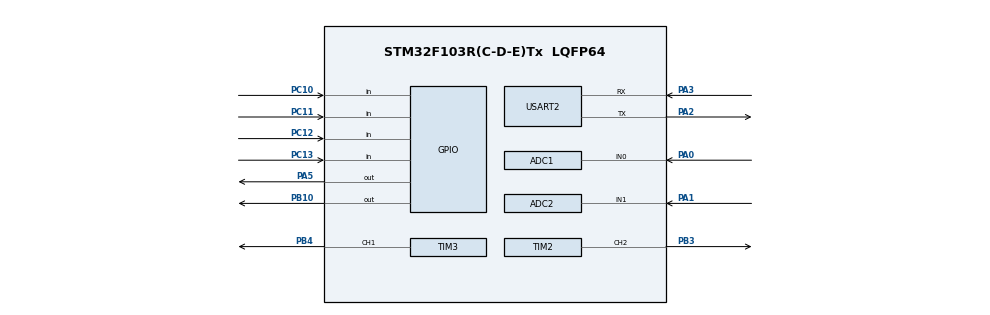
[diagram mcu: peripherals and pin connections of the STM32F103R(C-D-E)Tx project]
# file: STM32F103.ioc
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ADC1.Channel-0\#ChannelRegularConversion=ADC_CHANNEL_0
ADC1.ContinuousConvMode=DISABLE
ADC1.NbrOfConversionFlag=1
ADC1.Rank-0\#ChannelRegularConversion=1
ADC1.SamplingTime-0\#ChannelRegularConversion=ADC_SAMPLETIME_1CYCLE_5
ADC1.master=1
ADC2.Channel-2\#ChannelRegularConversion=ADC_CHANNEL_1
ADC2.NbrOfConversionFlag=1
ADC2.Rank-2\#ChannelRegularConversion=1
ADC2.SamplingTime-2\#ChannelRegularConversion=ADC_SAMPLETIME_1CYCLE_5
Mcu.Family=STM32F1
Mcu.Name=STM32F103R(C-D-E)Tx
Mcu.Package=LQFP64
NVIC.PriorityGroup=NVIC_PRIORITYGROUP_4
PA0-WKUP.Signal=ADCx_IN0
PA1.Signal=ADCx_IN1
PA13.Mode=Serial_Wire
PA13.Signal=SYS_JTMS-SWDIO
PA14.Mode=Serial_Wire
PA14.Signal=SYS_JTCK-SWCLK
PA2.Mode=Asynchronous
PA2.Signal=USART2_TX
PA3.Mode=Asynchronous
PA3.Signal=USART2_RX
PA5.Signal=GPIO_Output
PB10.Signal=GPIO_Output
PB3.Signal=S_TIM2_CH2
PB4.Signal=S_TIM3_CH1
PC10.GPIO_PuPd=GPIO_PULLUP
PC10.Signal=GPIO_Input
PC11.GPIO_PuPd=GPIO_PULLUP
PC11.Signal=GPIO_Input
PC12.GPIO_PuPd=GPIO_PULLUP
PC12.Signal=GPIO_Input
PC13-TAMPER-RTC.Signal=GPIO_Input
PC14-OSC32_IN.Mode=LSE-External-Oscillator
PC14-OSC32_IN.Signal=RCC_OSC32_IN
PC15-OSC32_OUT.Mode=LSE-External-Oscillator
PC15-OSC32_OUT.Signal=RCC_OSC32_OUT
PD0-OSC_IN.Mode=HSE-External-Oscillator
PD0-OSC_IN.Signal=RCC_OSC_IN
PD1-OSC_OUT.Mode=HSE-External-Oscillator
PD1-OSC_OUT.Signal=RCC_OSC_OUT
ProjectManager.HeapSize=0x200
ProjectManager.StackSize=0x400
ProjectManager.TargetToolchain=MDK-ARM V5.27
RCC.APB1Freq_Value=8000000
RCC.APB2Freq_Value=8000000
RCC.SYSCLKSource=RCC_SYSCLKSOURCE_HSE
SH.ADCx_IN0.0=ADC1_IN0,IN0
SH.ADCx_IN1.0=ADC2_IN1,IN1
SH.S_TIM2_CH2.0=TIM2_CH2,PWM Generation2 CH2
SH.S_TIM3_CH1.0=TIM3_CH1,PWM Generation1 CH1
TIM2.AutoReloadPreload=TIM_AUTORELOAD_PRELOAD_ENABLE
TIM2.Channel-PWM\ Generation2\ CH2=TIM_CHANNEL_2
TIM2.Period=9
TIM2.Prescaler=7
TIM2.Pulse-PWM\ Generation2\ CH2=5
TIM3.AutoReloadPreload=TIM_AUTORELOAD_PRELOAD_ENABLE
TIM3.Channel-PWM\ Generation1\ CH1=TIM_CHANNEL_1
TIM3.Period=9
TIM3.Prescaler=7
TIM3.Pulse-PWM\ Generation1\ CH1=4
USART2.Parity=PARITY_NONE
USART2.VirtualMode=VM_ASYNC
USART2.WordLength=WORDLENGTH_8B
board=custom

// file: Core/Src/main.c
/* USER CODE BEGIN Header */
/**
  ******************************************************************************
  * @file           : main.c
  * @brief          : Main program body
  ******************************************************************************
  * @attention
  *
  * <h2><center>&copy; Copyright (c) 2023 STMicroelectronics.
  * All rights reserved.</center></h2>
  *
  * This software component is licensed by ST under BSD 3-Clause license,
  * the "License"; You may not use this file except in compliance with the
  * License. You may obtain a copy of the License at:
  *                        opensource.org/licenses/BSD-3-Clause
  *
  ******************************************************************************
  */
/* USER CODE END Header */
#include "main.h"

/* USER CODE BEGIN Includes */
#include "User_Code.h"
/* USER CODE END Includes */

ADC_HandleTypeDef hadc1;
ADC_HandleTypeDef hadc2;

TIM_HandleTypeDef htim2;
TIM_HandleTypeDef htim3;

UART_HandleTypeDef huart2;

void SystemClock_Config(void);
static void MX_GPIO_Init(void);
static void MX_TIM2_Init(void);
static void MX_USART2_UART_Init(void);
static void MX_ADC1_Init(void);
static void MX_TIM3_Init(void);
static void MX_ADC2_Init(void);

int main(void)
{

  /* MCU Configuration--------------------------------------------------------*/

  /* Reset of all peripherals, Initializes the Flash interface and the Systick. */
  HAL_Init();

  /* Configure the system clock */
  SystemClock_Config();

  /* Initialize all configured peripherals */
  MX_GPIO_Init();
  MX_TIM2_Init();
  MX_USART2_UART_Init();
  MX_ADC1_Init();
  MX_TIM3_Init();
  MX_ADC2_Init();

  /* Infinite loop */
  /* USER CODE BEGIN WHILE */

	HAL_TIM_PWM_Start (&htim2, TIM_CHANNEL_2);
	HAL_TIM_PWM_Start (&htim3, TIM_CHANNEL_1);
	HAL_GPIO_WritePin (GPIOB, GPIO_PIN_10, GPIO_PIN_SET);
	char is_rising = 1;

	float pressure_in_mm_hg = 0.0;
	while (1)
  {
		HAL_ADC_Start(&hadc1);
		HAL_ADC_Start(&hadc2);
		while(!(ADC1->SR & ADC_SR_EOC)) ;
		while(!(ADC2->SR & ADC_SR_EOC)) ;
		uint16_t adc1_value = HAL_ADC_GetValue(&hadc1);
		uint16_t adc2_value= HAL_ADC_GetValue(&hadc2);

		pressure_in_mm_hg = adc_to_hg_mm(adc1_value);

		char string1[6];
		char string2[6];

		string1[0] = '$';
		int_to_string(adc2_value, (string1 + 1), 4);
		string1[5] = ' ';
		float_to_string(pressure_in_mm_hg, string2, 5, 1);
		string2[5] = ';';

		HAL_UART_Transmit(&huart2, (uint8_t*) string1, 6, 1000);
		HAL_UART_Transmit(&huart2, (uint8_t*) string2, 6, 1000);

		if (pressure_in_mm_hg >= 200.0) {
			HAL_TIM_PWM_Stop (&htim2, TIM_CHANNEL_2);
			HAL_GPIO_WritePin (GPIOB, GPIO_PIN_10, GPIO_PIN_RESET);
			is_rising = 0;
		}
		if (!is_rising&&(pressure_in_mm_hg <= 40.0))
			HAL_TIM_PWM_Stop (&htim3, TIM_CHANNEL_1);

		HAL_Delay(1);

  }
}

void SystemClock_Config(void)
{
  RCC_OscInitTypeDef RCC_OscInitStruct = {0};
  RCC_ClkInitTypeDef RCC_ClkInitStruct = {0};
  RCC_PeriphCLKInitTypeDef PeriphClkInit = {0};

  /** Initializes the RCC Oscillators according to the specified parameters
  * in the RCC_OscInitTypeDef structure.
  */
  RCC_OscInitStruct.OscillatorType = RCC_OSCILLATORTYPE_HSE;
  RCC_OscInitStruct.HSEState = RCC_HSE_ON;
  RCC_OscInitStruct.PLL.PLLState = RCC_PLL_NONE;
  if (HAL_RCC_OscConfig(&RCC_OscInitStruct) != HAL_OK)
  {
    Error_Handler();
  }
  /** Initializes the CPU, AHB and APB buses clocks
  */
  RCC_ClkInitStruct.ClockType = RCC_CLOCKTYPE_HCLK|RCC_CLOCKTYPE_SYSCLK
                              |RCC_CLOCKTYPE_PCLK1|RCC_CLOCKTYPE_PCLK2;
  RCC_ClkInitStruct.SYSCLKSource = RCC_SYSCLKSOURCE_HSE;
  RCC_ClkInitStruct.AHBCLKDivider = RCC_SYSCLK_DIV1;
  RCC_ClkInitStruct.APB1CLKDivider = RCC_HCLK_DIV1;
  RCC_ClkInitStruct.APB2CLKDivider = RCC_HCLK_DIV1;

  if (HAL_RCC_ClockConfig(&RCC_ClkInitStruct, FLASH_LATENCY_0) != HAL_OK)
  {
    Error_Handler();
  }
  PeriphClkInit.PeriphClockSelection = RCC_PERIPHCLK_ADC;
  PeriphClkInit.AdcClockSelection = RCC_ADCPCLK2_DIV2;
  if (HAL_RCCEx_PeriphCLKConfig(&PeriphClkInit) != HAL_OK)
  {
    Error_Handler();
  }
}

static void MX_ADC1_Init(void)
{

  ADC_ChannelConfTypeDef sConfig = {0};

  /** Common config
  */
  hadc1.Instance = ADC1;
  hadc1.Init.ScanConvMode = ADC_SCAN_DISABLE;
  hadc1.Init.ContinuousConvMode = DISABLE;
  hadc1.Init.DiscontinuousConvMode = DISABLE;
  hadc1.Init.ExternalTrigConv = ADC_SOFTWARE_START;
  hadc1.Init.DataAlign = ADC_DATAALIGN_RIGHT;
  hadc1.Init.NbrOfConversion = 1;
  if (HAL_ADC_Init(&hadc1) != HAL_OK)
  {
    Error_Handler();
  }
  /** Configure Regular Channel
  */
  sConfig.Channel = ADC_CHANNEL_0;
  sConfig.Rank = ADC_REGULAR_RANK_1;
  sConfig.SamplingTime = ADC_SAMPLETIME_1CYCLE_5;
  if (HAL_ADC_ConfigChannel(&hadc1, &sConfig) != HAL_OK)
  {
    Error_Handler();
  }

}

static void MX_ADC2_Init(void)
{

  ADC_ChannelConfTypeDef sConfig = {0};

  /** Common config
  */
  hadc2.Instance = ADC2;
  hadc2.Init.ScanConvMode = ADC_SCAN_DISABLE;
  hadc2.Init.ContinuousConvMode = DISABLE;
  hadc2.Init.DiscontinuousConvMode = DISABLE;
  hadc2.Init.ExternalTrigConv = ADC_SOFTWARE_START;
  hadc2.Init.DataAlign = ADC_DATAALIGN_RIGHT;
  hadc2.Init.NbrOfConversion = 1;
  if (HAL_ADC_Init(&hadc2) != HAL_OK)
  {
    Error_Handler();
  }
  /** Configure Regular Channel
  */
  sConfig.Channel = ADC_CHANNEL_1;
  sConfig.Rank = ADC_REGULAR_RANK_1;
  sConfig.SamplingTime = ADC_SAMPLETIME_1CYCLE_5;
  if (HAL_ADC_ConfigChannel(&hadc2, &sConfig) != HAL_OK)
  {
    Error_Handler();
  }

}

static void MX_TIM2_Init(void)
{

  TIM_MasterConfigTypeDef sMasterConfig = {0};
  TIM_OC_InitTypeDef sConfigOC = {0};

  htim2.Instance = TIM2;
  htim2.Init.Prescaler = 7;
  htim2.Init.CounterMode = TIM_COUNTERMODE_UP;
  htim2.Init.Period = 9;
  htim2.Init.ClockDivision = TIM_CLOCKDIVISION_DIV1;
  htim2.Init.AutoReloadPreload = TIM_AUTORELOAD_PRELOAD_ENABLE;
  if (HAL_TIM_PWM_Init(&htim2) != HAL_OK)
  {
    Error_Handler();
  }
  sMasterConfig.MasterOutputTrigger = TIM_TRGO_RESET;
  sMasterConfig.MasterSlaveMode = TIM_MASTERSLAVEMODE_DISABLE;
  if (HAL_TIMEx_MasterConfigSynchronization(&htim2, &sMasterConfig) != HAL_OK)
  {
    Error_Handler();
  }
  sConfigOC.OCMode = TIM_OCMODE_PWM1;
  sConfigOC.Pulse = 5;
  sConfigOC.OCPolarity = TIM_OCPOLARITY_HIGH;
  sConfigOC.OCFastMode = TIM_OCFAST_DISABLE;
  if (HAL_TIM_PWM_ConfigChannel(&htim2, &sConfigOC, TIM_CHANNEL_2) != HAL_OK)
  {
    Error_Handler();
  }
  HAL_TIM_MspPostInit(&htim2);

}

static void MX_TIM3_Init(void)
{

  TIM_MasterConfigTypeDef sMasterConfig = {0};
  TIM_OC_InitTypeDef sConfigOC = {0};

  htim3.Instance = TIM3;
  htim3.Init.Prescaler = 7;
  htim3.Init.CounterMode = TIM_COUNTERMODE_UP;
  htim3.Init.Period = 9;
  htim3.Init.ClockDivision = TIM_CLOCKDIVISION_DIV1;
  htim3.Init.AutoReloadPreload = TIM_AUTORELOAD_PRELOAD_ENABLE;
  if (HAL_TIM_PWM_Init(&htim3) != HAL_OK)
  {
    Error_Handler();
  }
  sMasterConfig.MasterOutputTrigger = TIM_TRGO_RESET;
  sMasterConfig.MasterSlaveMode = TIM_MASTERSLAVEMODE_DISABLE;
  if (HAL_TIMEx_MasterConfigSynchronization(&htim3, &sMasterConfig) != HAL_OK)
  {
    Error_Handler();
  }
  sConfigOC.OCMode = TIM_OCMODE_PWM1;
  sConfigOC.Pulse = 4;
  sConfigOC.OCPolarity = TIM_OCPOLARITY_HIGH;
  sConfigOC.OCFastMode = TIM_OCFAST_DISABLE;
  if (HAL_TIM_PWM_ConfigChannel(&htim3, &sConfigOC, TIM_CHANNEL_1) != HAL_OK)
  {
    Error_Handler();
  }
  HAL_TIM_MspPostInit(&htim3);

}

static void MX_USART2_UART_Init(void)
{

  huart2.Instance = USART2;
  huart2.Init.BaudRate = 115200;
  huart2.Init.WordLength = UART_WORDLENGTH_8B;
  huart2.Init.StopBits = UART_STOPBITS_1;
  huart2.Init.Parity = UART_PARITY_NONE;
  huart2.Init.Mode = UART_MODE_TX_RX;
  huart2.Init.HwFlowCtl = UART_HWCONTROL_NONE;
  huart2.Init.OverSampling = UART_OVERSAMPLING_16;
  if (HAL_UART_Init(&huart2) != HAL_OK)
  {
    Error_Handler();
  }

}

static void MX_GPIO_Init(void)
{
  GPIO_InitTypeDef GPIO_InitStruct = {0};

  /* GPIO Ports Clock Enable */
  __HAL_RCC_GPIOC_CLK_ENABLE();
  __HAL_RCC_GPIOD_CLK_ENABLE();
  __HAL_RCC_GPIOA_CLK_ENABLE();
  __HAL_RCC_GPIOB_CLK_ENABLE();

  /*Configure GPIO pin Output Level */
  HAL_GPIO_WritePin(GPIOA, GPIO_PIN_5, GPIO_PIN_RESET);

  /*Configure GPIO pin Output Level */
  HAL_GPIO_WritePin(GPIOB, GPIO_PIN_10, GPIO_PIN_RESET);

  /*Configure GPIO pin : PC13 */
  GPIO_InitStruct.Pin = GPIO_PIN_13;
  GPIO_InitStruct.Mode = GPIO_MODE_INPUT;
  GPIO_InitStruct.Pull = GPIO_NOPULL;
  HAL_GPIO_Init(GPIOC, &GPIO_InitStruct);

  /*Configure GPIO pin : PA5 */
  GPIO_InitStruct.Pin = GPIO_PIN_5;
  GPIO_InitStruct.Mode = GPIO_MODE_OUTPUT_PP;
  GPIO_InitStruct.Pull = GPIO_NOPULL;
  GPIO_InitStruct.Speed = GPIO_SPEED_FREQ_LOW;
  HAL_GPIO_Init(GPIOA, &GPIO_InitStruct);

  /*Configure GPIO pin : PB10 */
  GPIO_InitStruct.Pin = GPIO_PIN_10;
  GPIO_InitStruct.Mode = GPIO_MODE_OUTPUT_PP;
  GPIO_InitStruct.Pull = GPIO_NOPULL;
  GPIO_InitStruct.Speed = GPIO_SPEED_FREQ_LOW;
  HAL_GPIO_Init(GPIOB, &GPIO_InitStruct);

  /*Configure GPIO pins : PC10 PC11 PC12 */
  GPIO_InitStruct.Pin = GPIO_PIN_10|GPIO_PIN_11|GPIO_PIN_12;
  GPIO_InitStruct.Mode = GPIO_MODE_INPUT;
  GPIO_InitStruct.Pull = GPIO_PULLUP;
  HAL_GPIO_Init(GPIOC, &GPIO_InitStruct);

}

void Error_Handler(void)
{
  __disable_irq();
  while (1)
  {
  }
}

/************************ (C) COPYRIGHT STMicroelectronics *****END OF FILE****/
